# EVE1_SCTM register map
Vendor: Texas Instruments
Peripheral module from a debugger description file (folder DRA74xP_75xP_76xP_77xP).
Registers are 32-bit, access per field, reset values left out (the file's numbers can be read two ways) unless marked. A register's access mark holds for its fields unless they carry their own. Offsets are as the file gives them; lines under a group give offsets from that group; [hi:lo] are bit positions; {n}, {i} and the like mark numbered series; 'fields as' and 'values as' point back to an identical list; <NAME> marks a mode.

## EVE1_SCTM
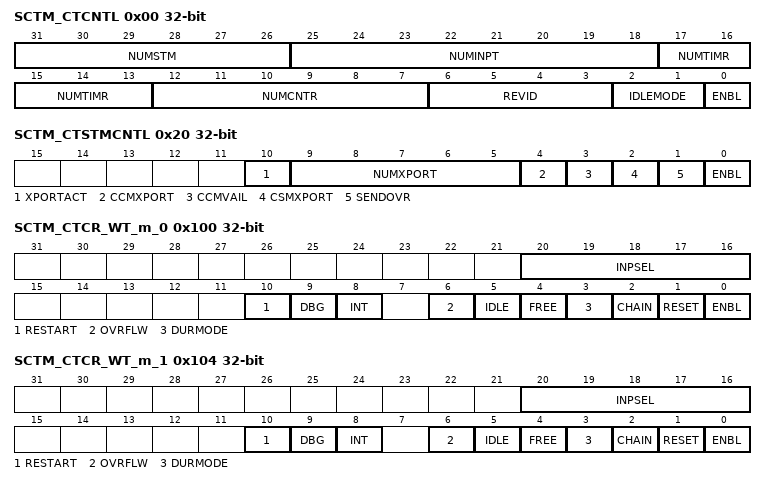
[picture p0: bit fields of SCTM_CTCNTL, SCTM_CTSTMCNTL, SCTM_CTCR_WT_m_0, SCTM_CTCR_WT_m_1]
0x00 SCTM_CTCNTL
  [31:26] NUMSTM ro — Number of timers that can export through STM
  [25:18] NUMINPT ro — Number of event input signals
  [17:13] NUMTIMR ro — Number of timers in the module
  [12:7] NUMCNTR ro — Number of counters in the module
  [6:3] REVID ro — Revision ID of SCTM
  [2:1] IDLEMODE rw — Idle mode control 0x0: Force Idle mode 0x1: Ths SCTM will acknoledge the idle request, but never transition to the idle state 0x3: Since the SCTM does not support internal wakeup, this mode is identical to smart_idle 0x2: Ths SCTM uses the smart idle protocol. This is the default mode
  [0] ENBL rw — SCTM global enable
    0=DISABLE; 1=ENABLE
0x20 SCTM_CTSTMCNTL — This register contains the control and status settings for STM export
  [10] XPORTACT ro — Indicates if a frame is currently being written to the STM
  [9:5] NUMXPORT rw — The total number of counters designated for export. this will be used as the count in the CSM and CCM headers. The value written should be the total number of counters designated for export -1
  [4] CCMXPORT rw — SW control of CCM message export
  [3] CCMVAIL ro — SCTM supports CCM export
  [2] CSMXPORT rw — SW control of CSM message export
  [1] SENDOVR rw — Send overflow data in CSM frame
  [0] ENBL rw — STM global enable
    0=DISABLE; 1=ENABLE
0x24 SCTM_CTSTMMSTID
  [6:0] MASTID rw — HW Master ID for this module.
0x28 SCTM_CTSTMINTVL
  [15:0] INTERVAL rw — Periodic export interval
0x2C SCTM_CTSTMSEL rw — These registers mark the counters selected for export in the CSM
  [31:0] COUNTSEL — The counter selection bit field
{0x40+4i} SCTM_TINTVLR_i_{i} rw (i=0..7) — These registers contain the interval match value for the corresponding timers in the SCTM
  [31:0] INTERVAL — Interval match value for the timers in the SCTM
0x7C SCTM_CTDBGNUM ro — Counter Timer Number Debug Event Register
  [2:0] NUMEVT — Number of input selectors for debug events
0x80 SCTM_CTDBGEVT — Counter Timer Debug Event Register
  [7:0] INPSEL rw — Index of event input signal on the module boundary
0xF0 SCTM_CTGNBL — These registers provide for simultaneous enable/disable of 32 counters
  [7:0] ENABLE rw — The counter enable bit field
0xF8 SCTM_CTGRST — These registers provide for simultaneous reset of 32 counters
  [7:0] RESET rw — The counter reset bit field
0x100 SCTM_CTCR_WT_m_0 — These registers contain the control and status settings for a single counter in the module. There will be a CTCR for every counter in the module (WT: with timer)
  [20:16] INPSEL rw — Counter Timer input selection
  [10] RESTART rw — Restart the timer after an interval match
  [9] DBG rw — Signal debug logic on interval match
  [8] INT rw — Generate interrupt on interval match
  [6] OVRFLW ro — Counter has wrapped since it was last read
  [5] IDLE rw — Counter ignores processor IDLE state
  [4] FREE rw — Counter ignores processor debug halt state
  [3] DURMODE rw — Counter is in duration or occurrence mode
  [2] CHAIN rw — Counter is chained to an adjacent counter
  [1] RESET rw — Counter reset control
  [0] ENBL rw — Counter enable control
0x104 SCTM_CTCR_WT_m_1 — These registers contain the control and status settings for a single counter in the module. There will be a CTCR for every counter in the module (WT: with timer)
  fields as SCTM_CTCR_WT_m_0
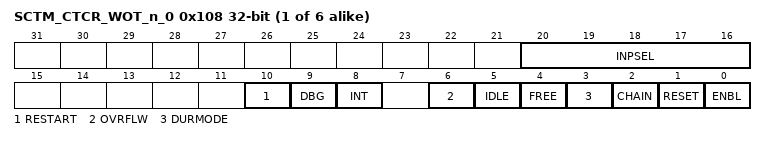
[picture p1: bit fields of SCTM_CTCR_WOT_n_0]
{0x108+4i} SCTM_CTCR_WOT_n_{i} (i=0..5) — These registers contain the control and status settings for a single counter in the module. There will be a CTCR for every counter in the module (WOT: without timer)
  fields as SCTM_CTCR_WT_m_0
{0x180+4i} SCTM_CTCNTR_k_{i} ro (i=0..7) — These registers contain the value of an individual counter in the moduel. There will be a CTCNTR for every counter in the module
  [31:0] COUNT — Counter value
